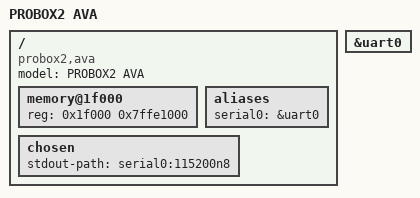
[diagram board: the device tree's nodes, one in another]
/dts-v1/;
#include "rtd1295.dtsi"
/ {
	compatible = "probox2,ava", "realtek,rtd1295";
	model = "PROBOX2 AVA";
	memory@1f000 {
		device_type = "memory";
		reg = <0x1f000 0x7ffe1000>;  
	};
	aliases {
		serial0 = &uart0;
	};
	chosen {
		stdout-path = "serial0:115200n8";
	};
};
&uart0 {
	status = "okay";
};
